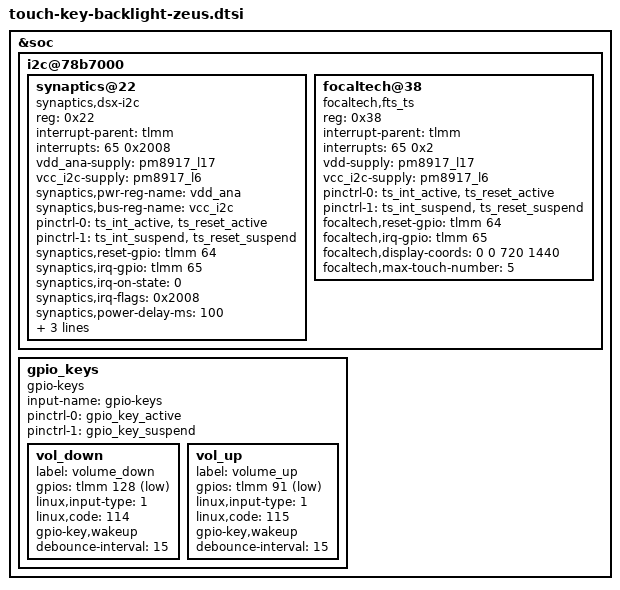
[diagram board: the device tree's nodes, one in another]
/*for touchscreen and key*/

&soc {

	i2c@78b7000 {
		status = "ok";
		synaptics@22 {
			compatible = "synaptics,dsx-i2c";
			reg = <0x22>;
			interrupt-parent = <&tlmm>;
			interrupts = <65 0x2008>;
			vdd_ana-supply = <&pm8917_l17>;
			vcc_i2c-supply = <&pm8917_l6>;
			synaptics,pwr-reg-name = "vdd_ana";
			synaptics,bus-reg-name = "vcc_i2c";
			pinctrl-names = "pmx_ts_active", "pmx_ts_suspend";
			pinctrl-0 = <&ts_int_active &ts_reset_active>;
			pinctrl-1 = <&ts_int_suspend &ts_reset_suspend>;
			synaptics,reset-gpio = <&tlmm 64 0x0>;
			synaptics,irq-gpio = <&tlmm 65 0x0>;
			synaptics,irq-on-state = <0>;
			synaptics,irq-flags = <0x2008>; /* IRQF_ONESHOT | IRQF_TRIGGER_LOW */
			synaptics,power-delay-ms = <100>;
			synaptics,reset-delay-ms = <100>;
			synaptics,reset-on-state = <0>;
			synaptics,reset-active-ms = <20>;
		};
		focaltech@38{
			compatible = "focaltech,fts_ts";
			reg = <0x38>;
			interrupt-parent = <&tlmm>;
			interrupts = <65 0x2>;
			vdd-supply = <&pm8917_l17>;
			vcc_i2c-supply = <&pm8917_l6>;
			pinctrl-names = "pmx_ts_active", "pmx_ts_suspend";
			pinctrl-0 = <&ts_int_active &ts_reset_active>;
			pinctrl-1 = <&ts_int_suspend &ts_reset_suspend>;
			focaltech,reset-gpio = <&tlmm 64 0x0>;
			focaltech,irq-gpio = <&tlmm 65 0x2002>;
			focaltech,display-coords = <0 0 720 1440>;
			focaltech,max-touch-number = <5>;
	};

	};

	gpio_keys {
		compatible = "gpio-keys";
		input-name = "gpio-keys";
		pinctrl-names = "tlmm_gpio_key_active","tlmm_gpio_key_suspend";
		pinctrl-0 = <&gpio_key_active>;
		pinctrl-1 = <&gpio_key_suspend>;

		vol_down {
				label = "volume_down";
				gpios = <&tlmm 128 0x1>;
				linux,input-type = <1>;
				linux,code = <114>;
				gpio-key,wakeup;
				debounce-interval = <15>;
			};
		vol_up {
				label = "volume_up";
				gpios = <&tlmm 91 0x1>;
				linux,input-type = <1>;
				linux,code = <115>;
				gpio-key,wakeup;
				debounce-interval = <15>;
			};
	};

};
